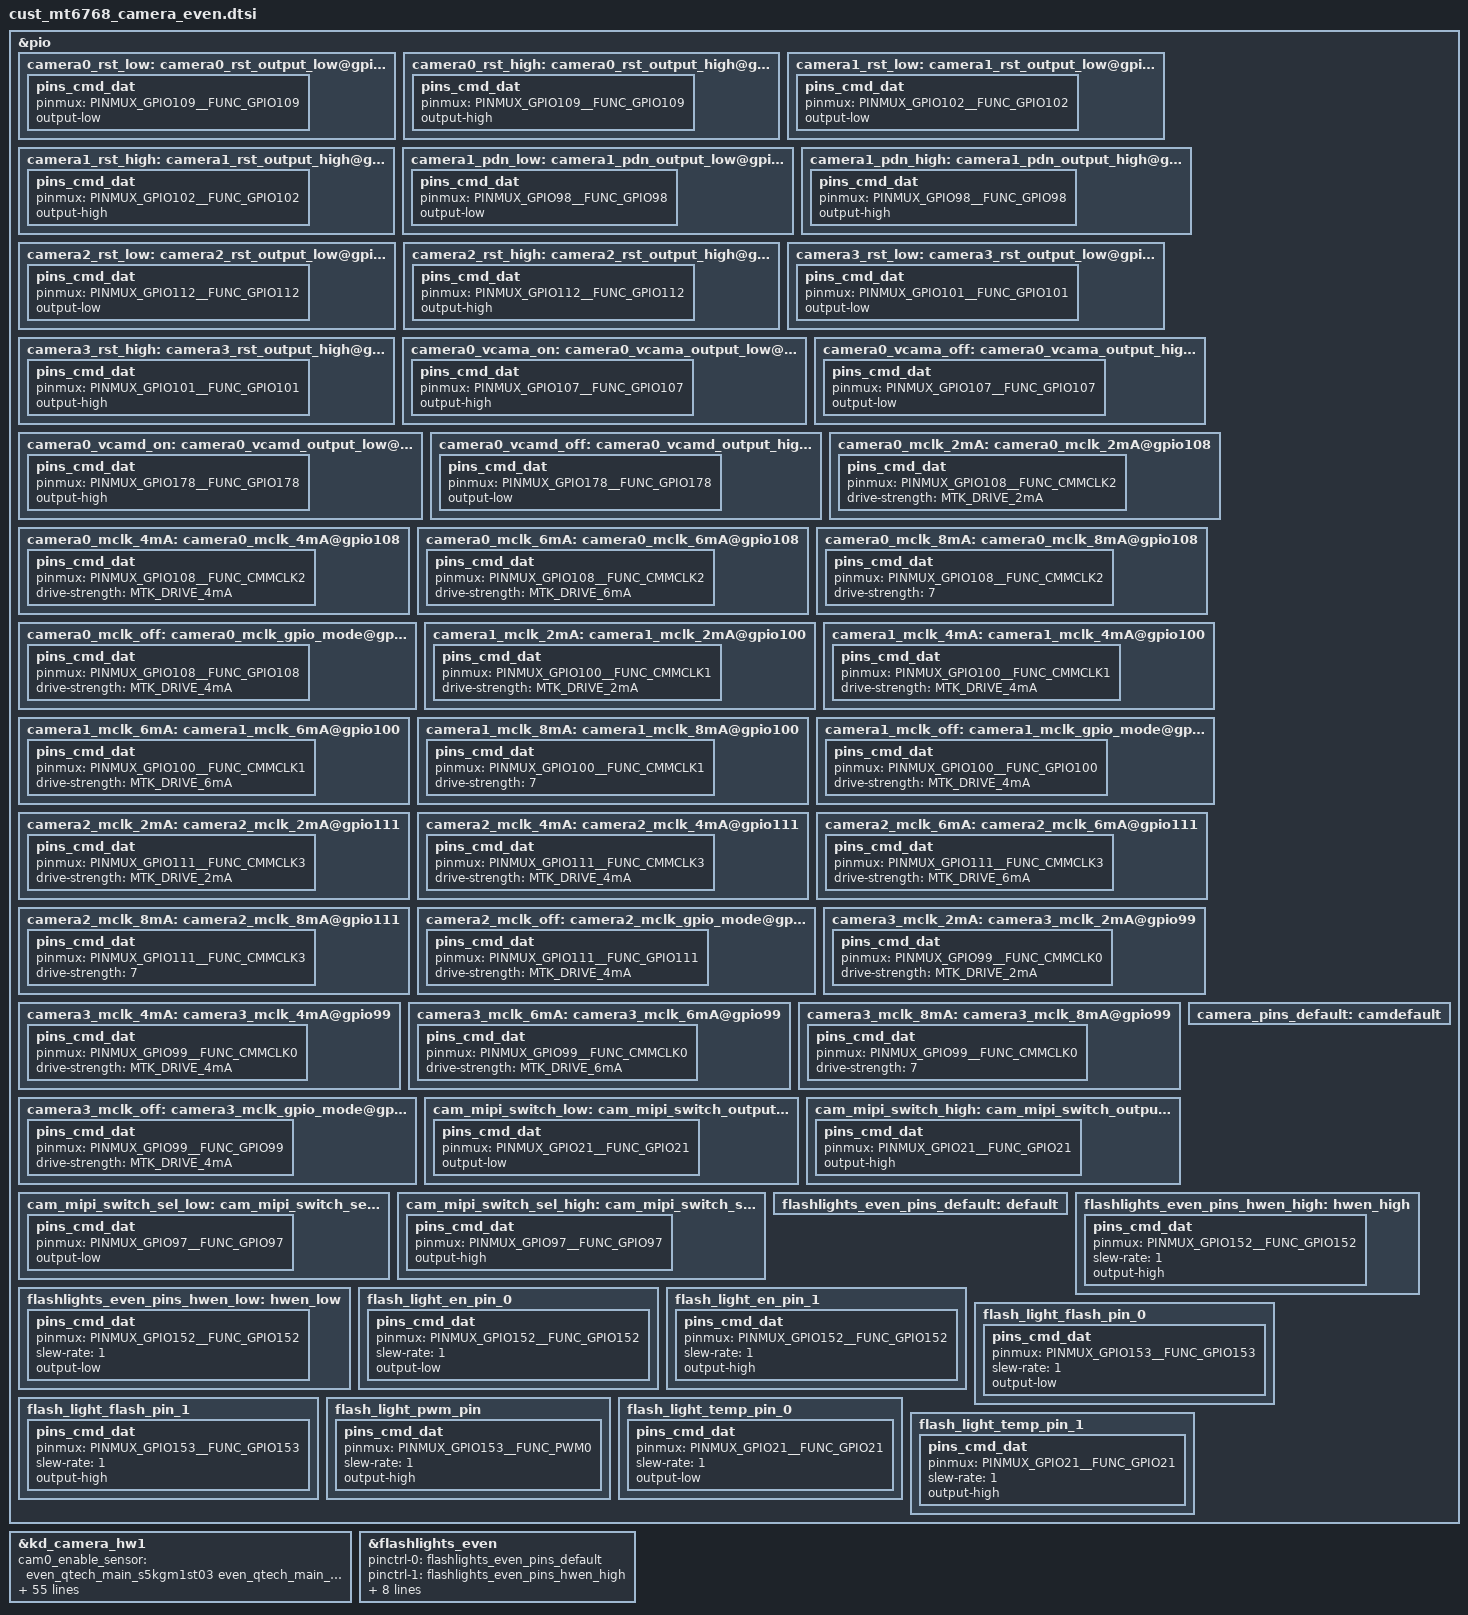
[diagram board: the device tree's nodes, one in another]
/*
 * Copyright (c) 2019 MediaTek Inc.
 *
 * This program is free software; you can redistribute it and/or modify
 * it under the terms of the GNU General Public License version 2 as
 * published by the Free Software Foundation.
 *
 * This program is distributed in the hope that it will be useful,
 * but WITHOUT ANY WARRANTY; without even the implied warranty of
 * MERCHANTABILITY or FITNESS FOR A PARTICULAR PURPOSE.  See the
 * GNU General Public License for more details.
 */
/* CAMERA GPIO standardization */
&pio {
	camera0_rst_low: camera0_rst_output_low@gpio109 {
		pins_cmd_dat {
			pinmux = <PINMUX_GPIO109__FUNC_GPIO109>;
			output-low;
		};
	};
	camera0_rst_high: camera0_rst_output_high@gpio109 {
		pins_cmd_dat {
			pinmux = <PINMUX_GPIO109__FUNC_GPIO109>;
			output-high;
		};
	};
	camera1_rst_low: camera1_rst_output_low@gpio102 {
		pins_cmd_dat {
			pinmux = <PINMUX_GPIO102__FUNC_GPIO102>;
			output-low;
		};
	};
	camera1_rst_high: camera1_rst_output_high@gpio102 {
		pins_cmd_dat {
			pinmux = <PINMUX_GPIO102__FUNC_GPIO102>;
			output-high;
		};
	};
	camera1_pdn_low: camera1_pdn_output_low@gpio98 {
		pins_cmd_dat {
			pinmux = <PINMUX_GPIO98__FUNC_GPIO98>;
			output-low;
		};
	};
	camera1_pdn_high: camera1_pdn_output_high@gpio98 {
		pins_cmd_dat {
			pinmux = <PINMUX_GPIO98__FUNC_GPIO98>;
			output-high;
		};
	};
	camera2_rst_low: camera2_rst_output_low@gpio112 {
		pins_cmd_dat {
			pinmux = <PINMUX_GPIO112__FUNC_GPIO112>;
			output-low;
		};
	};
	camera2_rst_high: camera2_rst_output_high@gpio112 {
		pins_cmd_dat {
			pinmux = <PINMUX_GPIO112__FUNC_GPIO112>;
			output-high;
		};
	};
	camera3_rst_low: camera3_rst_output_low@gpio101 {
		pins_cmd_dat {
			pinmux = <PINMUX_GPIO101__FUNC_GPIO101>;
			output-low;
		};
	};
	camera3_rst_high: camera3_rst_output_high@gpio101 {
		pins_cmd_dat {
			pinmux = <PINMUX_GPIO101__FUNC_GPIO101>;
			output-high;
		};
	};
	camera0_vcama_on: camera0_vcama_output_low@gpio107 {
		pins_cmd_dat {
			pinmux = <PINMUX_GPIO107__FUNC_GPIO107>;
			output-high;
		};
	};
	camera0_vcama_off: camera0_vcama_output_high@gpio107 {
		pins_cmd_dat {
			pinmux = <PINMUX_GPIO107__FUNC_GPIO107>;
			output-low;
		};
	};
	camera0_vcamd_on: camera0_vcamd_output_low@gpio178 {
		pins_cmd_dat {
			pinmux = <PINMUX_GPIO178__FUNC_GPIO178>;
			output-high;
		};
	};
	camera0_vcamd_off: camera0_vcamd_output_high@gpio178 {
		pins_cmd_dat {
			pinmux = <PINMUX_GPIO178__FUNC_GPIO178>;
			output-low;
		};
	};
	camera0_mclk_2mA: camera0_mclk_2mA@gpio108 {
		pins_cmd_dat {
			pinmux = <PINMUX_GPIO108__FUNC_CMMCLK2>;
			drive-strength = <MTK_DRIVE_2mA>;
		};
	};
	camera0_mclk_4mA: camera0_mclk_4mA@gpio108 {
		pins_cmd_dat {
			pinmux = <PINMUX_GPIO108__FUNC_CMMCLK2>;
			drive-strength = <MTK_DRIVE_4mA>;
		};
	};
	camera0_mclk_6mA: camera0_mclk_6mA@gpio108 {
		pins_cmd_dat {
			pinmux = <PINMUX_GPIO108__FUNC_CMMCLK2>;
			drive-strength = <MTK_DRIVE_6mA>;
		};
	};
	camera0_mclk_8mA: camera0_mclk_8mA@gpio108 {
		pins_cmd_dat {
			pinmux = <PINMUX_GPIO108__FUNC_CMMCLK2>;
			drive-strength = <7>;
		};
	};
	camera0_mclk_off: camera0_mclk_gpio_mode@gpio108 {
		pins_cmd_dat {
			pinmux = <PINMUX_GPIO108__FUNC_GPIO108>;
			drive-strength = <MTK_DRIVE_4mA>;
		};
	};
	camera1_mclk_2mA: camera1_mclk_2mA@gpio100 {
		pins_cmd_dat {
			pinmux = <PINMUX_GPIO100__FUNC_CMMCLK1>;
			drive-strength = <MTK_DRIVE_2mA>;
		};
	};
	camera1_mclk_4mA: camera1_mclk_4mA@gpio100 {
		pins_cmd_dat {
			pinmux = <PINMUX_GPIO100__FUNC_CMMCLK1>;
			drive-strength = <MTK_DRIVE_4mA>;
		};
	};
	camera1_mclk_6mA: camera1_mclk_6mA@gpio100 {
		pins_cmd_dat {
			pinmux = <PINMUX_GPIO100__FUNC_CMMCLK1>;
			drive-strength = <MTK_DRIVE_6mA>;
		};
	};
	camera1_mclk_8mA: camera1_mclk_8mA@gpio100 {
		pins_cmd_dat {
			pinmux = <PINMUX_GPIO100__FUNC_CMMCLK1>;
			drive-strength = <7>;
		};
	};
	camera1_mclk_off: camera1_mclk_gpio_mode@gpio100 {
		pins_cmd_dat {
			pinmux = <PINMUX_GPIO100__FUNC_GPIO100>;
			drive-strength = <MTK_DRIVE_4mA>;
		};
	};
	camera2_mclk_2mA: camera2_mclk_2mA@gpio111 {
		pins_cmd_dat {
			pinmux = <PINMUX_GPIO111__FUNC_CMMCLK3>;
			drive-strength = <MTK_DRIVE_2mA>;
		};
	};
	camera2_mclk_4mA: camera2_mclk_4mA@gpio111 {
		pins_cmd_dat {
			pinmux = <PINMUX_GPIO111__FUNC_CMMCLK3>;
			drive-strength = <MTK_DRIVE_4mA>;
		};
	};
	camera2_mclk_6mA: camera2_mclk_6mA@gpio111 {
		pins_cmd_dat {
			pinmux = <PINMUX_GPIO111__FUNC_CMMCLK3>;
			drive-strength = <MTK_DRIVE_6mA>;
		};
	};
	camera2_mclk_8mA: camera2_mclk_8mA@gpio111 {
		pins_cmd_dat {
			pinmux = <PINMUX_GPIO111__FUNC_CMMCLK3>;
			drive-strength = <7>;
		};
	};
	camera2_mclk_off: camera2_mclk_gpio_mode@gpio111 {
		pins_cmd_dat {
			pinmux = <PINMUX_GPIO111__FUNC_GPIO111>;
			drive-strength = <MTK_DRIVE_4mA>;
		};
	};
	camera3_mclk_2mA: camera3_mclk_2mA@gpio99 {
		pins_cmd_dat {
			pinmux = <PINMUX_GPIO99__FUNC_CMMCLK0>;
			drive-strength = <MTK_DRIVE_2mA>;
		};
	};
	camera3_mclk_4mA: camera3_mclk_4mA@gpio99 {
		pins_cmd_dat {
			pinmux = <PINMUX_GPIO99__FUNC_CMMCLK0>;
			drive-strength = <MTK_DRIVE_4mA>;
		};
	};
	camera3_mclk_6mA: camera3_mclk_6mA@gpio99 {
		pins_cmd_dat {
			pinmux = <PINMUX_GPIO99__FUNC_CMMCLK0>;
			drive-strength = <MTK_DRIVE_6mA>;
		};
	};
	camera3_mclk_8mA: camera3_mclk_8mA@gpio99 {
		pins_cmd_dat {
			pinmux = <PINMUX_GPIO99__FUNC_CMMCLK0>;
			drive-strength = <7>;
		};
	};
	camera3_mclk_off: camera3_mclk_gpio_mode@gpio99 {
		pins_cmd_dat {
			pinmux = <PINMUX_GPIO99__FUNC_GPIO99>;
			drive-strength = <MTK_DRIVE_4mA>;
		};
	};
	cam_mipi_switch_low: cam_mipi_switch_output_low@gpio21 {
		pins_cmd_dat {
			pinmux = <PINMUX_GPIO21__FUNC_GPIO21>;
			output-low;
		};
	};
	cam_mipi_switch_high: cam_mipi_switch_output_high@gpio21 {
		pins_cmd_dat {
			pinmux = <PINMUX_GPIO21__FUNC_GPIO21>;
			output-high;
		};
	};
	cam_mipi_switch_sel_low: cam_mipi_switch_sel_output_low@gpio97 {
		pins_cmd_dat {
			pinmux = <PINMUX_GPIO97__FUNC_GPIO97>;
			output-low;
		};
	};
	cam_mipi_switch_sel_high: cam_mipi_switch_sel_output_high@gpio97 {
		pins_cmd_dat {
			pinmux = <PINMUX_GPIO97__FUNC_GPIO97>;
			output-high;
		};
	};
	camera_pins_default: camdefault {
	};

};

&kd_camera_hw1 {
	cam0_enable_sensor = "even_qtech_main_s5kgm1st03 even_qtech_main_ov13b10";
	cam1_enable_sensor = "even_hlt_front_s5k4h7 even_shengtai_front_ov8856";
	cam2_enable_sensor = "even_hlt_depth_gc02m1b";
	cam3_enable_sensor = "even_shengtai_macro_ov02b10";

	pinctrl-names = "default",
			"cam0_rst0", "cam0_rst1",
			"cam1_rst0", "cam1_rst1",
			"cam1_pnd0", "cam1_pnd1",
			"cam2_rst0", "cam2_rst1",
			"cam3_rst0", "cam3_rst1",
			"cam0_vcama_on",
			"cam0_vcama_off",
			"cam0_vcamd_on",
			"cam0_vcamd_off",
			"cam0_mclk_off",
			"cam0_mclk_2mA", "cam0_mclk_4mA",
			"cam0_mclk_6mA", "cam0_mclk_8mA",
			"cam1_mclk_off",
			"cam1_mclk_2mA", "cam1_mclk_4mA",
			"cam1_mclk_6mA", "cam1_mclk_8mA",
			"cam2_mclk_off",
			"cam2_mclk_2mA", "cam2_mclk_4mA",
			"cam2_mclk_6mA", "cam2_mclk_8mA",
			"cam3_mclk_off",
			"cam3_mclk_2mA", "cam3_mclk_4mA",
			"cam3_mclk_6mA", "cam3_mclk_8mA",
			"cam_mipi_switch_en_0", "cam_mipi_switch_en_1",
			"cam_mipi_switch_sel_0", "cam_mipi_switch_sel_1";


	pinctrl-0 = <&camera_pins_default>;
	pinctrl-1 = <&camera0_rst_low>;
	pinctrl-2 = <&camera0_rst_high>;
	pinctrl-3 = <&camera1_rst_low>;
	pinctrl-4 = <&camera1_rst_high>;
	pinctrl-5 = <&camera1_pdn_low>;
	pinctrl-6 = <&camera1_pdn_high>;
	pinctrl-7 = <&camera2_rst_low>;
	pinctrl-8 = <&camera2_rst_high>;
	pinctrl-9 = <&camera3_rst_low>;
	pinctrl-10 = <&camera3_rst_high>;
	pinctrl-11 = <&camera0_vcama_on>;
	pinctrl-12 = <&camera0_vcama_off>;
	pinctrl-13 = <&camera0_vcamd_on>;
	pinctrl-14 = <&camera0_vcamd_off>;
	pinctrl-15 = <&camera0_mclk_off>;
	pinctrl-16 = <&camera0_mclk_2mA>;
	pinctrl-17 = <&camera0_mclk_4mA>;
	pinctrl-18 = <&camera0_mclk_6mA>;
	pinctrl-19 = <&camera0_mclk_8mA>;
	pinctrl-20 = <&camera1_mclk_off>;
	pinctrl-21 = <&camera1_mclk_2mA>;
	pinctrl-22 = <&camera1_mclk_4mA>;
	pinctrl-23 = <&camera1_mclk_6mA>;
	pinctrl-24 = <&camera1_mclk_8mA>;
	pinctrl-25 = <&camera2_mclk_off>;
	pinctrl-26 = <&camera2_mclk_2mA>;
	pinctrl-27 = <&camera2_mclk_4mA>;
	pinctrl-28 = <&camera2_mclk_6mA>;
	pinctrl-29 = <&camera2_mclk_8mA>;
	pinctrl-30 = <&camera3_mclk_off>;
	pinctrl-31 = <&camera3_mclk_2mA>;
	pinctrl-32 = <&camera3_mclk_4mA>;
	pinctrl-33 = <&camera3_mclk_6mA>;
	pinctrl-34 = <&camera3_mclk_8mA>;
	pinctrl-35 = <&cam_mipi_switch_low>;
	pinctrl-36 = <&cam_mipi_switch_high>;
	pinctrl-37 = <&cam_mipi_switch_sel_low>;
	pinctrl-38 = <&cam_mipi_switch_sel_high>;


	cam0_vcamio-supply = <&mt_pmic_vcamio_ldo_reg>;
	cam1_vcamio-supply = <&mt_pmic_vcamio_ldo_reg>;
	cam2_vcamio-supply = <&mt_pmic_vcamio_ldo_reg>;
	cam3_vcamio-supply = <&mt_pmic_vcamio_ldo_reg>;
	cam0_vcamaf-supply = <&mt_pmic_vldo28_ldo_reg>;

	cam1_vcama-supply = <&mt_pmic_vcama1_ldo_reg>;
	cam1_vcamd-supply = <&mt_pmic_vcamd_ldo_reg>;
	cam2_vcama-supply = <&mt_pmic_vcama1_ldo_reg>;
	cam3_vcama-supply = <&mt_pmic_vcama2_ldo_reg>;
	cam2_vcamd-supply = <&mt_pmic_vcamd_ldo_reg>;
	cam0_vcamd-supply = <&mt_pmic_vcamd_ldo_reg>;

	status = "okay";

};
&flashlights_even {
        pinctrl-names = "default",
                "hwen_high",
                "hwen_low",
                "flash_light_en_pin_0",
                "flash_light_en_pin_1",
                "flash_light_flash_pin_0",
                "flash_light_flash_pin_1",
                "flash_light_pwm_pin",
                "flash_light_temp_pin_0",
                "flash_light_temp_pin_1";

        pinctrl-0 = <&flashlights_even_pins_default>;
        pinctrl-1 = <&flashlights_even_pins_hwen_high>;
        pinctrl-2 = <&flashlights_even_pins_hwen_low>;
        pinctrl-3 = <&flash_light_en_pin_0>;
        pinctrl-4 = <&flash_light_en_pin_1>;
        pinctrl-5 = <&flash_light_flash_pin_0>;
        pinctrl-6 = <&flash_light_flash_pin_1>;
        pinctrl-7 = <&flash_light_pwm_pin>;
        pinctrl-8 = <&flash_light_temp_pin_0>;
        pinctrl-9 = <&flash_light_temp_pin_1>;

        status = "okay";
};

&pio {
        flashlights_even_pins_default:default {
        };
        flashlights_even_pins_hwen_high: hwen_high {
                pins_cmd_dat {
                        pinmux = <PINMUX_GPIO152__FUNC_GPIO152>;
                        slew-rate = <1>;
                        output-high;
                };
        };
        flashlights_even_pins_hwen_low: hwen_low {
                pins_cmd_dat {
                        pinmux = <PINMUX_GPIO152__FUNC_GPIO152>;
                        slew-rate = <1>;
                        output-low;
                };
        };

        flash_light_en_pin_0: flash_light_en_pin_0 {
                pins_cmd_dat {
                        pinmux = <PINMUX_GPIO152__FUNC_GPIO152>;
                        slew-rate = <1>;
                        output-low;
                };
        };
        flash_light_en_pin_1: flash_light_en_pin_1 {
                pins_cmd_dat {
                        pinmux = <PINMUX_GPIO152__FUNC_GPIO152>;
                        slew-rate = <1>;
                        output-high;
                };
        };
        flash_light_flash_pin_0: flash_light_flash_pin_0 {
                pins_cmd_dat {
                        pinmux = <PINMUX_GPIO153__FUNC_GPIO153>;
                        slew-rate = <1>;
                        output-low;
                };
        };
        flash_light_flash_pin_1: flash_light_flash_pin_1 {
                pins_cmd_dat {
                        pinmux = <PINMUX_GPIO153__FUNC_GPIO153>;
                        slew-rate = <1>;
                        output-high;
                };
        };
        flash_light_pwm_pin: flash_light_pwm_pin {
                pins_cmd_dat {
                        pinmux = <PINMUX_GPIO153__FUNC_PWM0>;
                        slew-rate = <1>;
                        output-high;
                };
        };
        flash_light_temp_pin_0: flash_light_temp_pin_0 {
                pins_cmd_dat {
                        pinmux = <PINMUX_GPIO21__FUNC_GPIO21>;
                        slew-rate = <1>;
                        output-low;
                };
        };
        flash_light_temp_pin_1: flash_light_temp_pin_1 {
                pins_cmd_dat {
                        pinmux = <PINMUX_GPIO21__FUNC_GPIO21>;
                        slew-rate = <1>;
                        output-high;
                };
        };
};

/* CAMERA GPIO end */
